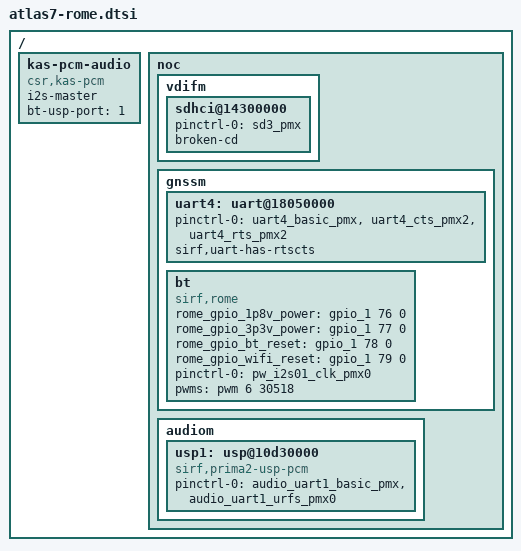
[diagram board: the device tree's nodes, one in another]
/*
 * DTS file for CSR SiRFatlas7 Evaluation Board installed with QCA6574 &
 *
 * Copyright (c) 2016, The Linux Foundation. All rights reserved.
 *
 * This program is free software; you can redistribute it and/or modify
 * it under the terms of the GNU General Public License version 2 and
 * only version 2 as published by the Free Software Foundation.
 *
 * This program is distributed in the hope that it will be useful,
 * but WITHOUT ANY WARRANTY; without even the implied warranty of
 * MERCHANTABILITY or FITNESS FOR A PARTICULAR PURPOSE.  See the
 * GNU General Public License for more details.
 */

/ {
	/*
	 *usp1 is set in atlas7-evb-common.dtsi, which is used by a7ca bt
	 */
	kas-pcm-audio {
		compatible = "csr,kas-pcm";
		i2s-master;
		bt-usp-port = <1>;
	};
	noc {
		vdifm {
			sdhci@14300000 {
				status = "okay";
				pinctrl-names = "default";
				pinctrl-0 = <&sd3_pmx>;
				broken-cd;
			};
		};
		gnssm {
			uart4: uart@18050000 {
				status = "okay";
				pinctrl-0 = <&uart4_basic_pmx
						&uart4_cts_pmx2
						&uart4_rts_pmx2>;
				pinctrl-names = "default";
				sirf,uart-has-rtscts;
			};
			bt {
				compatible = "sirf,rome";
				/* PIN:coex_pio_0 */
				rome_gpio_1p8v_power = <&gpio_1 76 0>;
				/* PIN:coex_pio_1 */
				rome_gpio_3p3v_power = <&gpio_1 77 0>;
				/* PIN:coex_pio_2 */
				rome_gpio_bt_reset = <&gpio_1 78 0>;
				/* PIN:coex_pio_3 */
				rome_gpio_wifi_reset = <&gpio_1 79 0>;
				pinctrl-names = "default";
				pinctrl-0 = <&pw_i2s01_clk_pmx0>;
				pwms = <&pwm 6 30518>;
			};
		};
		audiom {
			usp1: usp@10d30000 {
				status = "okay";
				#sound-dai-cells = <0>;
				compatible = "sirf,prima2-usp-pcm";
				pinctrl-names = "default";
				pinctrl-0 = <&audio_uart1_basic_pmx
						&audio_uart1_urfs_pmx0>;
			};
		};
	};
};
